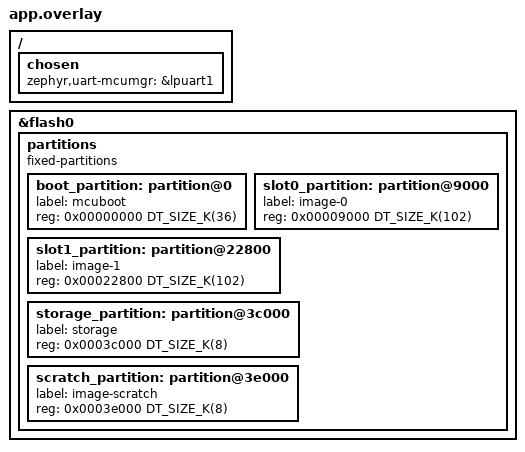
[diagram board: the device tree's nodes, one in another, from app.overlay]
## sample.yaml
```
sample:
  description: UART Boot sample for STM32WL55 Nucleo board
  name: STM32WL55 UART Boot Sample
  
common: 
    sysbuild: true
    build_only: true
    skip: true
    integration_platforms: 
      - nucleo_wl55jc
    platform_exclude:
      - native_sim
    
tests:
  stm32wl55.uart_boot: {}
```

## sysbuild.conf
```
# Add MCUboot
SB_CONFIG_BOOTLOADER_MCUBOOT=y

# Step 2.1 - Add private key for MCUboot

SB_CONFIG_BOOT_SIGNATURE_KEY_FILE="/workdir/boot_with_keys/private_key.pem"

# Step 2.2. - Configure key type

SB_CONFIG_BOOT_SIGNATURE_TYPE_ECDSA_P256=y


SB_CONFIG_MCUBOOT_MODE_SINGLE_APP=n
```

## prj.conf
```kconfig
# Enable GPIO driver for LED control
CONFIG_GPIO=y

# Enable console and logging for debugging
CONFIG_CONSOLE=y
CONFIG_UART_CONSOLE=y
CONFIG_SERIAL=y
CONFIG_PRINTK=y

# Enable MCUboot support
CONFIG_BOOTLOADER_MCUBOOT=y


# STEP 5.2 - Enable mcumgr DFU in application
# Enable MCUMGR 
CONFIG_MCUMGR=y

# Enable MCUMGR management for both OS and Images
CONFIG_MCUMGR_GRP_OS=y
CONFIG_MCUMGR_GRP_IMG=y

# Configure MCUMGR transport to UART
CONFIG_MCUMGR_TRANSPORT_UART=y

# Dependencies
# Configure dependencies for CONFIG_MCUMGR  
CONFIG_NET_BUF=y
CONFIG_ZCBOR=y
CONFIG_CRC=y

# Configure dependencies for CONFIG_MCUMGR_GRP_IMG  
CONFIG_FLASH=y
CONFIG_IMG_MANAGER=y

# Configure dependencies for CONFIG_IMG_MANAGER  
CONFIG_STREAM_FLASH=y
CONFIG_FLASH_MAP=y

# Configure dependencies for CONFIG_MCUMGR_TRANSPORT_UART 
CONFIG_BASE64=y
```

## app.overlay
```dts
/* Application overlay for MCUmgr UART transport */
/ {
    chosen {
        zephyr,uart-mcumgr = &lpuart1;
    };
};

/* 
 * Flash partition layout for STM32WL55JC (256KB total flash)
 * Must match the MCUboot overlay partition layout
 * Layout: 36KB boot + 102KB slot0 + 102KB slot1 + 8KB storage + 8KB scratch = 256KB
 */
&flash0 {
    /* Delete existing partitions node to avoid conflicts */
    /delete-node/ partitions;
    
    partitions {
        compatible = "fixed-partitions";
        #address-cells = <1>;
        #size-cells = <1>;

        /* MCUboot bootloader - 36KB at base address (minimum required) */
        boot_partition: partition@0 {
            label = "mcuboot";
            reg = <0x00000000 DT_SIZE_K(36)>;
        };

        /* Primary application slot (slot0) - 102KB */
        slot0_partition: partition@9000 {
            label = "image-0";
            reg = <0x00009000 DT_SIZE_K(102)>;
        };

        /* Secondary application slot (slot1) - 102KB */
        slot1_partition: partition@22800 {
            label = "image-1";
            reg = <0x00022800 DT_SIZE_K(102)>;
        };

        /* Storage partition - 8KB */
        storage_partition: partition@3c000 {
            label = "storage";
            reg = <0x0003c000 DT_SIZE_K(8)>;
        };

        /* Scratch area for image swapping - 8KB */
        scratch_partition: partition@3e000 {
            label = "image-scratch";
            reg = <0x0003e000 DT_SIZE_K(8)>;
        };
    };
};
```

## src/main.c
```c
/*
 * Copyright (c) 2016 Intel Corporation
 *
 * SPDX-License-Identifier: Apache-2.0
 */

#include <zephyr/kernel.h>
#include <zephyr/drivers/gpio.h>
#include <zephyr/sys/printk.h>

/* 1000 msec = 1 sec */

/* STEP 4.4 - Change LED timing to create a new image for DFU*/
#define SLEEP_TIME_MS   5000

/* The devicetree node identifier for the "led0" alias. */
#define LED0_NODE DT_ALIAS(led0)

/*
 * A build error on this line means your board is unsupported.
 * See the sample documentation for information on how to fix this.
 */
static const struct gpio_dt_spec led = GPIO_DT_SPEC_GET(LED0_NODE, gpios);

int main(void)
{
	int ret;

	printk("Starting LED blink application for Nucleo WL55JC\n");

	if (!device_is_ready(led.port)) {
		printk("Error: LED device not ready\n");
		return -1;
	}

	ret = gpio_pin_configure_dt(&led, GPIO_OUTPUT_ACTIVE);
	if (ret < 0) {
		printk("Error: Failed to configure LED GPIO\n");
		return -1;
	}

	printk("LED configured successfully, starting blink loop\n");

	while (1) {
		ret = gpio_pin_toggle_dt(&led);
		if (ret < 0) {
			printk("Error: Failed to toggle LED\n");
			return -1;
		}
		printk("LED toggled\n");
		k_msleep(SLEEP_TIME_MS);
	}
}
```
